AUTOSAR XML (schema 3.1.2)
package /Components/SWC_GSI
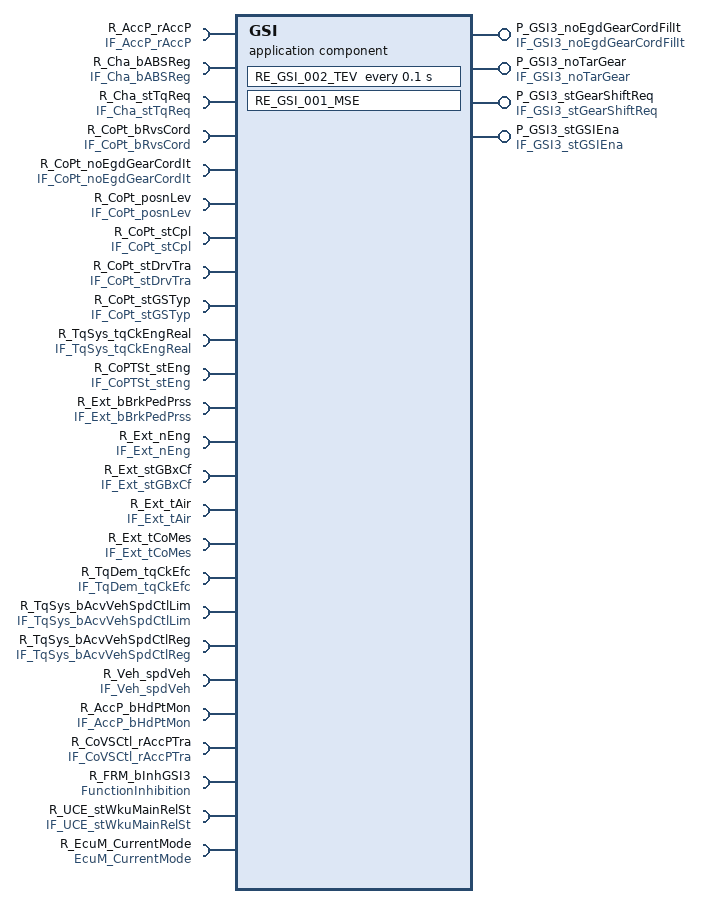
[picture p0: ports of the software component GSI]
  application software component type GSI
    23 x require port:
      R_AccP_rAccP: unqueued-receiver-com-spec{data-element=AccP_rAccP, init-value=ConstantValue, resync-time=0}, required-interface=IF_AccP_rAccP
      R_Cha_bABSReg: unqueued-receiver-com-spec{data-element=Cha_bABSReg, init-value=ConstantValue1, resync-time=0}, required-interface=IF_Cha_bABSReg
      R_Cha_stTqReq: unqueued-receiver-com-spec{data-element=Cha_stTqReq, init-value=ConstantValue3, resync-time=0}, required-interface=IF_Cha_stTqReq
      R_CoPt_bRvsCord: unqueued-receiver-com-spec{data-element=CoPt_bRvsCord, init-value=ConstantValue5, resync-time=0}, required-interface=IF_CoPt_bRvsCord
      R_CoPt_noEgdGearCordIt: unqueued-receiver-com-spec{data-element=CoPt_noEgdGearCordIt, init-value=ConstantValue7, resync-time=0}, required-interface=IF_CoPt_noEgdGearCordIt
      R_CoPt_posnLev: unqueued-receiver-com-spec{data-element=CoPt_posnLev, init-value=CoPt_posnLev_in, resync-time=0}, required-interface=IF_CoPt_posnLev
      R_CoPt_stCpl: unqueued-receiver-com-spec{data-element=CoPt_stCpl, init-value=ConstantValue9, resync-time=0}, required-interface=IF_CoPt_stCpl
      R_CoPt_stDrvTra: unqueued-receiver-com-spec{data-element=CoPt_stDrvTra, init-value=CoPt_stDrvTra_in, resync-time=0}, required-interface=IF_CoPt_stDrvTra
      R_CoPt_stGSTyp: unqueued-receiver-com-spec{data-element=CoPt_stGSTyp, init-value=CoPt_stGSTyp_in, resync-time=0}, required-interface=IF_CoPt_stGSTyp
      R_TqSys_tqCkEngReal: unqueued-receiver-com-spec{data-element=TqSys_tqCkEngReal, init-value=ConstantValue11, resync-time=0}, required-interface=IF_TqSys_tqCkEngReal
      R_CoPTSt_stEng: unqueued-receiver-com-spec{data-element=CoPTSt_stEng, init-value=ConstantValue13, resync-time=0}, required-interface=IF_CoPTSt_stEng
      R_Ext_bBrkPedPrss: unqueued-receiver-com-spec{data-element=Ext_bBrkPedPrss, init-value=Ext_bBrkPedPrss_in, resync-time=0}, required-interface=IF_Ext_bBrkPedPrss
      R_Ext_nEng: unqueued-receiver-com-spec{data-element=Ext_nEng, init-value=ConstantValue15, resync-time=0}, required-interface=IF_Ext_nEng
      R_Ext_stGBxCf: unqueued-receiver-com-spec{data-element=Ext_stGBxCf, init-value=ConstantValue17, resync-time=0}, required-interface=IF_Ext_stGBxCf
      R_Ext_tAir: unqueued-receiver-com-spec{data-element=Ext_tAir, init-value=ConstantValue19, resync-time=0}, required-interface=IF_Ext_tAir
      R_Ext_tCoMes: unqueued-receiver-com-spec{data-element=Ext_tCoMes, init-value=ConstantValue21, resync-time=0}, required-interface=IF_Ext_tCoMes
      R_TqDem_tqCkEfc: unqueued-receiver-com-spec{data-element=TqDem_tqCkEfc, init-value=ConstantValue23, resync-time=0}, required-interface=IF_TqDem_tqCkEfc
      R_TqSys_bAcvVehSpdCtlLim: unqueued-receiver-com-spec{data-element=TqSys_bAcvVehSpdCtlLim, init-value=TqSys_bAcvVehSpdCtlLim_in, resync-time=0}, required-interface=IF_TqSys_bAcvVehSpdCtlLim
      R_TqSys_bAcvVehSpdCtlReg: unqueued-receiver-com-spec{data-element=TqSys_bAcvVehSpdCtlReg, init-value=TqSys_bAcvVehSpdCtlReg_in, resync-time=0}, required-interface=IF_TqSys_bAcvVehSpdCtlReg
      R_Veh_spdVeh: unqueued-receiver-com-spec{data-element=Veh_spdVeh, init-value=ConstantValue25, resync-time=0}, required-interface=IF_Veh_spdVeh
      R_AccP_bHdPtMon: unqueued-receiver-com-spec{data-element=AccP_bHdPtMon, init-value=AccP_bHdPtMon_in, resync-time=0}, required-interface=IF_AccP_bHdPtMon
      R_CoVSCtl_rAccPTra: unqueued-receiver-com-spec{data-element=CoVSCtl_rAccPTra, init-value=CoVSCtl_rAccPTra_in, resync-time=0}, required-interface=IF_CoVSCtl_rAccPTra
      R_FRM_bInhGSI3: required-interface=FunctionInhibition
    4 x provide port:
      P_GSI3_noEgdGearCordFilIt: unqueued-sender-com-spec{data-element=GSI3_noEgdGearCordFilIt, can-invalidate=false, init-value=GSI3_noEgdGearCordFilIt_out}, provided-interface=IF_GSI3_noEgdGearCordFilIt
      P_GSI3_noTarGear: unqueued-sender-com-spec{data-element=GSI3_noTarGear, can-invalidate=false, init-value=GSI3_noTarGear_out}, provided-interface=IF_GSI3_noTarGear
      P_GSI3_stGearShiftReq: unqueued-sender-com-spec{data-element=GSI3_stGearShiftReq, can-invalidate=false, init-value=GSI3_stGearShiftReq_out}, provided-interface=IF_GSI3_stGearShiftReq
      P_GSI3_stGSIEna: unqueued-sender-com-spec{data-element=GSI3_stGSIEna, can-invalidate=false, init-value=GSI3_stGSIEna_out}, provided-interface=IF_GSI3_stGSIEna
    require port R_UCE_stWkuMainRelSt: required-interface=IF_UCE_stWkuMainRelSt
    require port R_EcuM_CurrentMode: required-interface=EcuM_CurrentMode
  26 x constant specification:
    AccP_bHdPtMon_in
      value:
        boolean literal AccP_bHdPtMon_in: type=DT_AccP_bHdPtMon, value=false
    ConstantValue
      value:
        integer literal ConstantValue: type=DT_AccP_rAccP, value=0
    ConstantValue1
      value:
        boolean literal ConstantValue1: type=DT_Cha_bABSReg, value=false
    ConstantValue11
      value:
        integer literal ConstantValue11: type=DT_TqSys_tqCkEngReal, value=0
    ConstantValue13
      value:
        integer literal ConstantValue13: type=DT_CoPTSt_stEng, value=1
    ConstantValue15
      value:
        integer literal ConstantValue15: type=DT_Ext_nEng, value=0
    ConstantValue17
      value:
        integer literal ConstantValue17: type=DT_Ext_stGBxCf, value=0
    ConstantValue19
      value:
        integer literal ConstantValue19: type=DT_Ext_tAir, value=20
    ConstantValue21
      value:
        integer literal ConstantValue21: type=DT_Ext_tCoMes, value=20
    ConstantValue23
      value:
        integer literal ConstantValue23: type=DT_TqDem_tqCkEfc, value=0
    ConstantValue25
      value:
        integer literal ConstantValue25: type=DT_Veh_spdVeh, value=0
    ConstantValue3
      value:
        integer literal ConstantValue3: type=DT_Cha_stTqReq, value=0
    ConstantValue5
      value:
        boolean literal ConstantValue5: type=DT_CoPt_bRvsCord, value=false
    ConstantValue7
      value:
        integer literal ConstantValue7: type=DT_CoPt_noEgdGearCordIt, value=0
    ConstantValue9
      value:
        integer literal ConstantValue9: type=DT_CoPt_stCpl, value=0
    CoPt_posnLev_in
      value:
        integer literal CoPt_posnLev_in: type=DT_CoPt_posnLev, value=0
    CoPt_stDrvTra_in
      value:
        boolean literal CoPt_stDrvTra_in: type=DT_CoPt_stDrvTra, value=false
    CoPt_stGSTyp_in
      value:
        integer literal CoPt_stGSTyp_in: type=DT_CoPt_stGSTyp, value=5
    CoVSCtl_rAccPTra_in
      value:
        integer literal CoVSCtl_rAccPTra_in: type=DT_CoVSCtl_rAccPTra, value=0
    Ext_bBrkPedPrss_in
      value:
        boolean literal Ext_bBrkPedPrss_in: type=DT_Ext_bBrkPedPrss, value=false
    GSI3_noEgdGearCordFilIt_out
      value:
        integer literal GSI3_noEgdGearCordFilIt_out: type=DT_GSI3_noEgdGearCordFilIt, value=0
    GSI3_noTarGear_out
      value:
        integer literal GSI3_noTarGear_out: type=DT_GSI3_noTarGear, value=9
    GSI3_stGearShiftReq_out
      value:
        integer literal GSI3_stGearShiftReq_out: type=DT_GSI3_stGearShiftReq, value=3
    GSI3_stGSIEna_out
      value:
        boolean literal GSI3_stGSIEna_out: type=DT_GSI3_stGSIEna, value=false
    TqSys_bAcvVehSpdCtlLim_in
      value:
        boolean literal TqSys_bAcvVehSpdCtlLim_in: type=DT_TqSys_bAcvVehSpdCtlLim, value=false
    TqSys_bAcvVehSpdCtlReg_in
      value:
        boolean literal TqSys_bAcvVehSpdCtlReg_in: type=DT_TqSys_bAcvVehSpdCtlReg, value=false
  internal behavior IB_GSI: component=GSI
    timing event EV_GSI_002_TEV: mode-dependency=dependent-on-mode=[R_UCE_stWkuMainRelSt.RCD_stWkuMainRelSt.PreMainWakeUp, R_UCE_stWkuMainRelSt.RCD_stWkuMainRelSt.PostMainWakeUp, R_UCE_stWkuMainRelSt.RCD_stWkuMainRelSt.Invalid], start-on-event=RE_GSI_002_TEV, period=0.1
    mode switch event EV_GSI_001_MSE: start-on-event=RE_GSI_001_MSE, activation=ENTRY, mode=R_EcuM_CurrentMode.currentMode.RUN
    runnable RE_GSI_002_TEV
      22 x data receive point:
        dr_Cha_stTqReq: data-element=R_Cha_stTqReq.Cha_stTqReq
        DR_CoPt_posnLev: data-element=R_CoPt_posnLev.CoPt_posnLev
        dr_CoPt_noEgdGearCordIt: data-element=R_CoPt_noEgdGearCordIt.CoPt_noEgdGearCordIt
        dr_Ext_tCoMes: data-element=R_Ext_tCoMes.Ext_tCoMes
        dr_TqSys_tqCkEngReal: data-element=R_TqSys_tqCkEngReal.TqSys_tqCkEngReal
        dr_Ext_stGBxCf: data-element=R_Ext_stGBxCf.Ext_stGBxCf
        dr_Ext_nEng: data-element=R_Ext_nEng.Ext_nEng
        DR_TqSys_bAcvVehSpdCtlReg: data-element=R_TqSys_bAcvVehSpdCtlReg.TqSys_bAcvVehSpdCtlReg
        dr_CoPTSt_stEng: data-element=R_CoPTSt_stEng.CoPTSt_stEng
        dr_Cha_bABSReg: data-element=R_Cha_bABSReg.Cha_bABSReg
        dr_CoPt_bRvsCord: data-element=R_CoPt_bRvsCord.CoPt_bRvsCord
        dr_AccP_rAccP: data-element=R_AccP_rAccP.AccP_rAccP
        DR_TqSys_bAcvVehSpdCtlLim: data-element=R_TqSys_bAcvVehSpdCtlLim.TqSys_bAcvVehSpdCtlLim
        DR_CoPt_stGSTyp: data-element=R_CoPt_stGSTyp.CoPt_stGSTyp
        DR_Ext_bBrkPedPrss: data-element=R_Ext_bBrkPedPrss.Ext_bBrkPedPrss
        dr_Veh_spdVeh: data-element=R_Veh_spdVeh.Veh_spdVeh
        DR_CoPt_stDrvTra: data-element=R_CoPt_stDrvTra.CoPt_stDrvTra
        dr_TqDem_tqCkEfc: data-element=R_TqDem_tqCkEfc.TqDem_tqCkEfc
        DR_CoVSCtl_rAccPTra: data-element=R_CoVSCtl_rAccPTra.CoVSCtl_rAccPTra
        dr_Ext_tAir: data-element=R_Ext_tAir.Ext_tAir
        DR_AccP_bHdPtMon: data-element=R_AccP_bHdPtMon.AccP_bHdPtMon
        dr_CoPt_stCpl: data-element=R_CoPt_stCpl.CoPt_stCpl
      4 x data send point:
        DS_GSI3_noTarGear: data-element=P_GSI3_noTarGear.GSI3_noTarGear
        DS_GSI3_stGSIEna: data-element=P_GSI3_stGSIEna.GSI3_stGSIEna
        DS_GSI3_stGearShiftReq: data-element=P_GSI3_stGearShiftReq.GSI3_stGearShiftReq
        DS_GSI3_noEgdGearCordFilIt: data-element=P_GSI3_noEgdGearCordFilIt.GSI3_noEgdGearCordFilIt
      sync call SC_FRM_bInhGSI3: operation=R_FRM_bInhGSI3.GetFunctionPermission
    runnable RE_GSI_001_MSE
      4 x data send point:
        DS_GSI3_noTarGear: data-element=P_GSI3_noTarGear.GSI3_noTarGear
        DS_GSI3_stGSIEna: data-element=P_GSI3_stGSIEna.GSI3_stGSIEna
        DS_GSI3_noEgdGearCordFilIt: data-element=P_GSI3_noEgdGearCordFilIt.GSI3_noEgdGearCordFilIt
        DS_GSI3_stGearShiftReq: data-element=P_GSI3_stGearShiftReq.GSI3_stGearShiftReq
  swc implementation Imp_GSI: programming-language=C, behavior=IB_GSI
    code-descriptors:
      code CodeDescriptor: type=SRC
        7 x xfile:
          GSI_002_TEV_fct_c: url=GSI_002_TEV_fct.c
          GSI_calibrations_h: url=GSI_calibrations.h
          GSI_002_TEV_fct_h: url=GSI_002_TEV_fct.h
          GSI_c: url=GSI.c
          GSI_MemMap_h: url=GSI_MemMap.h
          GSI_h: url=GSI.h
          GSI_calibrations_c: url=GSI_calibrations.c
